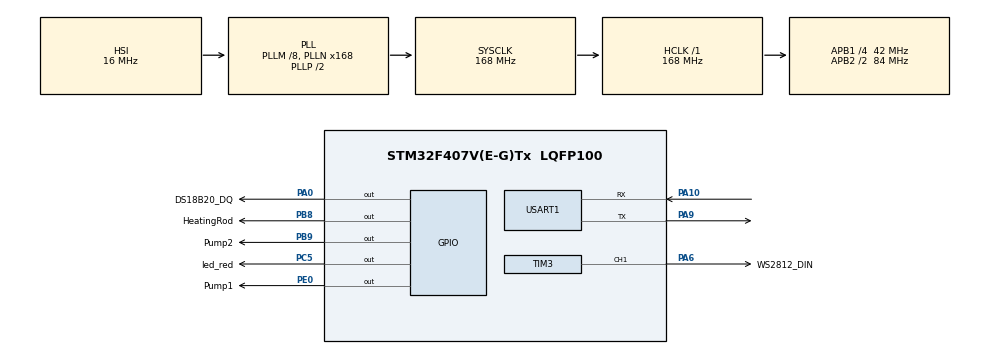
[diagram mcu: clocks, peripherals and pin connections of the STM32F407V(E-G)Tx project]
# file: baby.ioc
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Dma.Request0=TIM3_CH1/TRIG
Dma.TIM3_CH1/TRIG.0.Direction=DMA_MEMORY_TO_PERIPH
Dma.TIM3_CH1/TRIG.0.FIFOMode=DMA_FIFOMODE_DISABLE
Dma.TIM3_CH1/TRIG.0.Instance=DMA1_Stream4
Dma.TIM3_CH1/TRIG.0.MemDataAlignment=DMA_MDATAALIGN_HALFWORD
Dma.TIM3_CH1/TRIG.0.MemInc=DMA_MINC_ENABLE
Dma.TIM3_CH1/TRIG.0.Mode=DMA_NORMAL
Dma.TIM3_CH1/TRIG.0.PeriphDataAlignment=DMA_PDATAALIGN_HALFWORD
Dma.TIM3_CH1/TRIG.0.PeriphInc=DMA_PINC_DISABLE
Dma.TIM3_CH1/TRIG.0.Priority=DMA_PRIORITY_HIGH
Mcu.Family=STM32F4
Mcu.Name=STM32F407V(E-G)Tx
Mcu.Package=LQFP100
NVIC.DMA1_Stream4_IRQn=true\:0\:0\:false\:false\:true\:false\:true\:true
NVIC.PriorityGroup=NVIC_PRIORITYGROUP_4
NVIC.USART1_IRQn=true\:0\:0\:false\:false\:true\:true\:true\:true
PA0-WKUP.GPIO_Label=DS18B20_DQ
PA0-WKUP.GPIO_PuPd=GPIO_PULLUP
PA0-WKUP.GPIO_Speed=GPIO_SPEED_FREQ_VERY_HIGH
PA0-WKUP.PinState=GPIO_PIN_SET
PA0-WKUP.Signal=GPIO_Output
PA10.Mode=Asynchronous
PA10.Signal=USART1_RX
PA13.Mode=Serial_Wire
PA13.Signal=SYS_JTMS-SWDIO
PA14.Mode=Serial_Wire
PA14.Signal=SYS_JTCK-SWCLK
PA6.GPIO_Label=WS2812_DIN
PA6.GPIO_Speed=GPIO_SPEED_FREQ_VERY_HIGH
PA6.Signal=S_TIM3_CH1
PA9.Mode=Asynchronous
PA9.Signal=USART1_TX
PB8.GPIO_Label=HeatingRod
PB8.GPIO_PuPd=GPIO_PULLUP
PB8.GPIO_Speed=GPIO_SPEED_FREQ_VERY_HIGH
PB8.PinState=GPIO_PIN_SET
PB8.Signal=GPIO_Output
PB9.GPIO_Label=Pump2
PB9.GPIO_PuPd=GPIO_PULLUP
PB9.GPIO_Speed=GPIO_SPEED_FREQ_VERY_HIGH
PB9.PinState=GPIO_PIN_SET
PB9.Signal=GPIO_Output
PC14-OSC32_IN.Mode=LSE-External-Oscillator
PC14-OSC32_IN.Signal=RCC_OSC32_IN
PC15-OSC32_OUT.Mode=LSE-External-Oscillator
PC15-OSC32_OUT.Signal=RCC_OSC32_OUT
PC5.GPIO_Label=led_red
PC5.GPIO_PuPd=GPIO_PULLUP
PC5.GPIO_Speed=GPIO_SPEED_FREQ_VERY_HIGH
PC5.Signal=GPIO_Output
PE0.GPIO_Label=Pump1
PE0.GPIO_PuPd=GPIO_PULLUP
PE0.GPIO_Speed=GPIO_SPEED_FREQ_VERY_HIGH
PE0.PinState=GPIO_PIN_SET
PE0.Signal=GPIO_Output
PH0-OSC_IN.Mode=HSE-External-Oscillator
PH0-OSC_IN.Signal=RCC_OSC_IN
PH1-OSC_OUT.Mode=HSE-External-Oscillator
PH1-OSC_OUT.Signal=RCC_OSC_OUT
ProjectManager.HeapSize=0x200
ProjectManager.StackSize=0x400
ProjectManager.TargetToolchain=MDK-ARM V5.32
RCC.48MHZClocksFreq_Value=84000000
RCC.AHBFreq_Value=168000000
RCC.APB1CLKDivider=RCC_HCLK_DIV4
RCC.APB1Freq_Value=42000000
RCC.APB1TimFreq_Value=84000000
RCC.APB2CLKDivider=RCC_HCLK_DIV2
RCC.APB2Freq_Value=84000000
RCC.APB2TimFreq_Value=168000000
RCC.CortexFreq_Value=168000000
RCC.HCLKFreq_Value=168000000
RCC.HSE_VALUE=25000000
RCC.HSI_VALUE=16000000
RCC.PLLM=8
RCC.PLLN=168
RCC.SYSCLKFreq_VALUE=168000000
RCC.SYSCLKSource=RCC_SYSCLKSOURCE_PLLCLK
RCC.VCOOutputFreq_Value=336000000
SH.S_TIM3_CH1.0=TIM3_CH1,PWM Generation1 CH1
TIM3.Channel-PWM\ Generation1\ CH1=TIM_CHANNEL_1
TIM3.Period=104
USART1.VirtualMode=VM_ASYNC
board=custom

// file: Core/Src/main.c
/* USER CODE BEGIN Header */
/**
  ******************************************************************************
  * @file           : main.c
  * @brief          : Main program body
  ******************************************************************************
  * @attention
  *
  * Copyright (c) 2026 STMicroelectronics.
  * All rights reserved.
  *
  * This software is licensed under terms that can be found in the LICENSE file
  * in the root directory of this software component.
  * If no LICENSE file comes with this software, it is provided AS-IS.
  *
  ******************************************************************************
  */
/* USER CODE END Header */
#include "main.h"
#include "dma.h"
#include "tim.h"
#include "usart.h"
#include "gpio.h"

/* USER CODE BEGIN Includes */
#include "ds18b20.h"
#include "variables.hpp"
/* USER CODE END Includes */

void SystemClock_Config(void);

int main(void)
{

  /* MCU Configuration--------------------------------------------------------*/

  /* Reset of all peripherals, Initializes the Flash interface and the Systick. */
  HAL_Init();

  /* Configure the system clock */
  SystemClock_Config();

  /* Initialize all configured peripherals */
  MX_GPIO_Init();
  MX_DMA_Init();
  MX_USART1_UART_Init();
  MX_TIM3_Init();
  /* USER CODE BEGIN 2 */
  DS18B20_DelayInit();
  DS18B20_Init();

  /* USER CODE END 2 */

  /* Infinite loop */
  /* USER CODE BEGIN WHILE */
  while (1)
  {
      test_moter();
      test_ds18b20();
      HAL_Delay(10);
//      WS2812_SetAllColorBrightness(255, 140, 20, 10);
//
//      bspGpioToggle(led_red_GPIO_Port,led_red_Pin);
//      HAL_Delay(500);
//      bspGpioToggle(Pump1_GPIO_Port,Pump1_Pin);
//      HAL_Delay(500);
    /* USER CODE END WHILE */

  }
}

void SystemClock_Config(void)
{
  RCC_OscInitTypeDef RCC_OscInitStruct = {0};
  RCC_ClkInitTypeDef RCC_ClkInitStruct = {0};

  /** Configure the main internal regulator output voltage
  */
  __HAL_RCC_PWR_CLK_ENABLE();
  __HAL_PWR_VOLTAGESCALING_CONFIG(PWR_REGULATOR_VOLTAGE_SCALE1);

  /** Initializes the RCC Oscillators according to the specified parameters
  * in the RCC_OscInitTypeDef structure.
  */
  RCC_OscInitStruct.OscillatorType = RCC_OSCILLATORTYPE_HSI;
  RCC_OscInitStruct.HSIState = RCC_HSI_ON;
  RCC_OscInitStruct.HSICalibrationValue = RCC_HSICALIBRATION_DEFAULT;
  RCC_OscInitStruct.PLL.PLLState = RCC_PLL_ON;
  RCC_OscInitStruct.PLL.PLLSource = RCC_PLLSOURCE_HSI;
  RCC_OscInitStruct.PLL.PLLM = 8;
  RCC_OscInitStruct.PLL.PLLN = 168;
  RCC_OscInitStruct.PLL.PLLP = RCC_PLLP_DIV2;
  RCC_OscInitStruct.PLL.PLLQ = 4;
  if (HAL_RCC_OscConfig(&RCC_OscInitStruct) != HAL_OK)
  {
    Error_Handler();
  }

  /** Initializes the CPU, AHB and APB buses clocks
  */
  RCC_ClkInitStruct.ClockType = RCC_CLOCKTYPE_HCLK|RCC_CLOCKTYPE_SYSCLK
                              |RCC_CLOCKTYPE_PCLK1|RCC_CLOCKTYPE_PCLK2;
  RCC_ClkInitStruct.SYSCLKSource = RCC_SYSCLKSOURCE_PLLCLK;
  RCC_ClkInitStruct.AHBCLKDivider = RCC_SYSCLK_DIV1;
  RCC_ClkInitStruct.APB1CLKDivider = RCC_HCLK_DIV4;
  RCC_ClkInitStruct.APB2CLKDivider = RCC_HCLK_DIV2;

  if (HAL_RCC_ClockConfig(&RCC_ClkInitStruct, FLASH_LATENCY_5) != HAL_OK)
  {
    Error_Handler();
  }
}

void Error_Handler(void)
{
  __disable_irq();
  while (1)
  {
  }
}
